# ESP32-H21 register map
Vendor: ESPRESSIF SYSTEMS (SHANGHAI) CO., LTD.; Series: ESP32 H-Series; File version: 1
CPU: RV32IMAC r0p0, little endian, no MPU, no FPU, 0 interrupt priority bits
Address unit: 32 bits
Registers are 32-bit, read-write, reset 0x0 unless marked. A register's access mark holds for its fields unless they carry their own. Offsets are from the block's base; [hi:lo] are bit positions; {n}, {i} and the like mark numbered series.

## ECC — ECC (ECC Hardware Accelerator)
Base 0x6008B000
0x0C MULT_INT_RAW ro — ECC raw interrupt status register
  [0] CALC_DONE — The raw interrupt status of the ECC_CALC_DONE_INT interrupt.
0x10 MULT_INT_ST ro — ECC masked interrupt status register
  [0] CALC_DONE — The masked interrupt status of the ECC_CALC_DONE_INT interrupt.
0x14 MULT_INT_ENA — ECC interrupt enable register
  [0] CALC_DONE — Write 1 to enable the ECC_CALC_DONE_INT interrupt.
0x18 MULT_INT_CLR wo — ECC interrupt clear register
  [0] CALC_DONE write-1-clears — Write 1 to clear the ECC_CALC_DONE_INT interrupt.
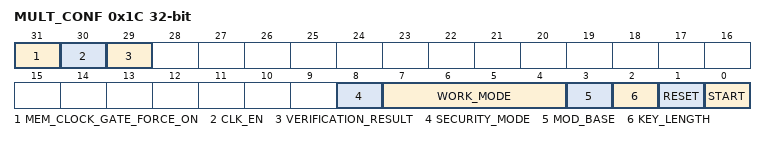
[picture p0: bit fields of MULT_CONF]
0x1C MULT_CONF access per field — ECC configuration register
  [31] MEM_CLOCK_GATE_FORCE_ON rw — Configures whether to force on ECC memory clock gate. \\ 0: No effect\\ 1: Force on\\
  [30] CLK_EN rw — Configures whether to force on register clock gate. \\ 0: No effect\\ 1: Force on\\
  [29] VERIFICATION_RESULT ro — Represents the verification result of ECC Accelerator, valid only when calculation is done.
  [8] SECURITY_MODE rw — Configures the security mode of ECC Accelerator.\\ 0: no secure function enabled.\\ 1: enable constant-time calculation in all point multiplication modes.\\
  [7:4] WORK_MODE rw — Configures the work mode of ECC Accelerator.\\ 0: Point Multi mode\\ 1: Reserved\\ 2: Point Verif mode\\ 3: Point Verif + Multi mode\\ 4: Jacobian Point Multi mode\\ 5: Reserved\\ 6: Jacobian Point Verif mode\\ 7: Point Verif + Jacobian Point Multi mode\\ 8: Mod Add mode\\ 9. Mod Sub mode\\ 10: Mod Multi mode\\ 11: Mod Div mode\\
  [3] MOD_BASE rw — Configures the mod base of mod operation, only valid in work_mode 8-11. \\ 0: n(order of curve)\\ 1: p(mod base of curve)\\
  [2] KEY_LENGTH rw — Configures the key length mode bit of ECC Accelerator. \\ 0: P-192\\ 1: P-256\\
    0=P192 (P-192 elliptic curve); 1=P256 (P-256 elliptic curve)
  [1] RESET wo — Configures whether to reset ECC Accelerator. \\ 0: No effect\\ 1: Reset\\
  [0] START rw — Configures whether to start calculation of ECC Accelerator. This bit will be self-cleared after the calculation is done. \\ 0: No effect\\ 1: Start calculation of ECC Accelerator\\
0xFC DATE — Version control register
{0x100+4i} K_MEM{i} (i=0..7) access not given — The memory that stores k.
{0x120+4i} PX_MEM{i} (i=0..7) access not given — The memory that stores Px.
{0x140+4i} PY_MEM{i} (i=0..7) access not given — The memory that stores Py.
{0x160+4i} QX_MEM{i} (i=0..7) access not given — The memory that stores Qx.
{0x180+4i} QY_MEM{i} (i=0..7) access not given — The memory that stores Qy.
{0x1A0+4i} QZ_MEM{i} (i=0..7) access not given — The memory that stores Qz.

## GPIO — General Purpose Input/Output
Base 0x60091000
0x00 STRAP ro — pad strapping register
  [15:0] STRAPPING
0x04 OUT — GPIO output register for GPIO0-29
  [29:0] DATA_ORIG
0x08 OUT_W1TS wo — GPIO output set register for GPIO0-29
  [29:0] OUT_W1TS
0x0C OUT_W1TC wo — GPIO output clear register for GPIO0-29
  [29:0] OUT_W1TC
0x34 ENABLE — GPIO output enable register for GPIO0-29
  [29:0] DATA
0x38 ENABLE_W1TS wo — GPIO output enable set register for GPIO0-29
  [29:0] ENABLE_W1TS
0x3C ENABLE_W1TC wo — GPIO output enable clear register for GPIO0-29
  [29:0] ENABLE_W1TC
0x64 IN ro — GPIO input register for GPIO0-29
  [29:0] DATA_NEXT
0x74 STATUS — GPIO interrupt status register for GPIO0-29
  [29:0] INTERRUPT
0x78 STATUS_W1TS wo — GPIO interrupt status set register for GPIO0-29
  [29:0] STATUS_W1TS
0x7C STATUS_W1TC wo — GPIO interrupt status clear register for GPIO0-29
  [29:0] STATUS_W1TC
0xA4 PCPU_INT ro — GPIO_PROCPU_INT interrupt status register for GPIO0-29
  [29:0] PROCPU_INT
0xA8 PCPU_NMI_INT ro — GPIO_PROCPU_NMI_INT interrupt status register for GPIO0-29
  [29:0] PROCPU_NMI_INT
0xC4 STATUS_NEXT ro — GPIO interrupt source register for GPIO0-29
  [29:0] STATUS_INTERRUPT_NEXT
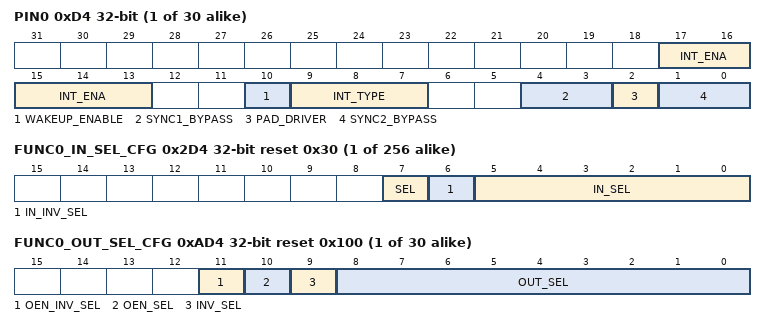
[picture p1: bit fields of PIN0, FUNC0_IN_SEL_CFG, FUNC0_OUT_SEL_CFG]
{0xD4+4i} PIN{i} (i=0..29) — GPIO pin configuration register
  [17:13] INT_ENA — set bit 13 to enable gpio_procpu_int. set bit 14 to enable gpio_procpu_nmi_int.
  [10] WAKEUP_ENABLE — set this bit to enable GPIO wakeup.(can only wakeup CPU from Light-sleep Mode)
  [9:7] INT_TYPE — set this value to choose interrupt mode. 0:disable GPIO interrupt. 1:trigger at posedge. 2:trigger at negedge. 3:trigger at any edge. 4:valid at low level. 5:valid at high level
  [4:3] SYNC1_BYPASS — set GPIO input_sync1 signal mode. 0:disable. 1:trigger at negedge. 2or3:trigger at posedge.
  [2] PAD_DRIVER — set this bit to select pad driver. 1:open-drain. 0:normal.
  [1:0] SYNC2_BYPASS — set GPIO input_sync2 signal mode. 0:disable. 1:trigger at negedge. 2or3:trigger at posedge.
{0x2D4+4i} FUNC{i}_IN_SEL_CFG (i=0..255) reset 0x30 — GPIO input function configuration register
  [7] SEL — Bypass GPIO matrix. 0: bypass. 1: route via GPIO matrix.
  [6] IN_INV_SEL — Invert the input value. 0: not invert. 1: invert.
  [5:0] IN_SEL — Select a pin for input signal %s. 0-29: GPIO[s]. 0x20: high. 0x30: low.
{0xAD4+4i} FUNC{i}_OUT_SEL_CFG (i=0..29) reset 0x100 — GPIO output function select register
  [11] OEN_INV_SEL — set this bit to invert output enable signal.1:invert.0:not invert.
  [10] OEN_SEL — set this bit to select output enable signal.1:use GPIO_ENABLE_REG[n] as output enable signal.0:use peripheral output enable signal.
  [9] INV_SEL — set this bit to invert output signal.1:invert.0:not invert.
  [8:0] OUT_SEL — The value of the bits: 0<=s<=256. Set the value to select output signal. s=0-127: output of GPIO[n] equals input of peripheral[s]. s=128: output of GPIO[n] equals GPIO_OUT_REG[n].
0xDF8 CLOCK_GATE reset 0x1 — GPIO clock gate register
  [0] CLK_EN — set this bit to enable GPIO clock gate
0xDFC DATE — GPIO version register
